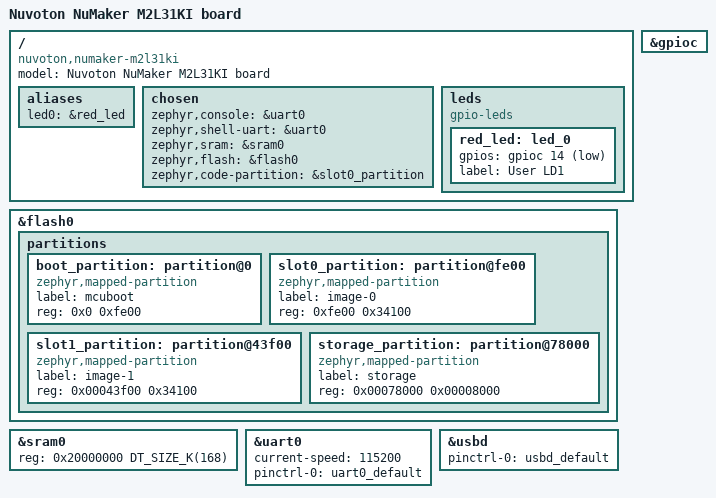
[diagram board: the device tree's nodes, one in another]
/*
 * Copyright (c) 2024 Nuvoton Technology Corporation.
 *
 * SPDX-License-Identifier: Apache-2.0
 */

/dts-v1/;

#include <nuvoton/m2l31kid.dtsi>
#include "numaker_m2l31ki-pinctrl.dtsi"
#include <zephyr/dt-bindings/input/input-event-codes.h>

/ {
	model = "Nuvoton NuMaker M2L31KI board";
	compatible = "nuvoton,numaker-m2l31ki";

	aliases {
		led0 = &red_led;
	};

	chosen {
		zephyr,console = &uart0;
		zephyr,shell-uart = &uart0;
		zephyr,sram = &sram0;
		zephyr,flash = &flash0;
		zephyr,code-partition = &slot0_partition;
	};

	leds {
		compatible = "gpio-leds";

		red_led: led_0 {
			gpios = <&gpioc 14 GPIO_ACTIVE_LOW>;
			label = "User LD1";
		};
	};
};

&gpioc {
	status = "okay";
};

&flash0 {
	partitions {
		ranges;
		#address-cells = <1>;
		#size-cells = <1>;

		boot_partition: partition@0 {
			compatible = "zephyr,mapped-partition";
			label = "mcuboot";
			reg = <0x0 0xfe00>;
		};

		slot0_partition: partition@fe00 {
			compatible = "zephyr,mapped-partition";
			label = "image-0";
			reg = <0xfe00 0x34100>;
		};

		slot1_partition: partition@43f00 {
			compatible = "zephyr,mapped-partition";
			label = "image-1";
			reg = <0x00043f00 0x34100>;
		};

		storage_partition: partition@78000 {
			compatible = "zephyr,mapped-partition";
			label = "storage";
			reg = <0x00078000 0x00008000>;
		};
	};
};

&sram0 {
	reg = <0x20000000 DT_SIZE_K(168)>;
};

&uart0 {
	current-speed = <115200>;
	pinctrl-0 = <&uart0_default>;
	pinctrl-names = "default";
	status = "okay";
};

/* On enabled, usbd is required to be clocked in 48MHz. */
zephyr_udc0: &usbd {
	pinctrl-0 = <&usbd_default>;
	pinctrl-names = "default";
	status = "okay";
};
